AUTOSAR XML (schema 4-2-2)
package /ComponentTypes
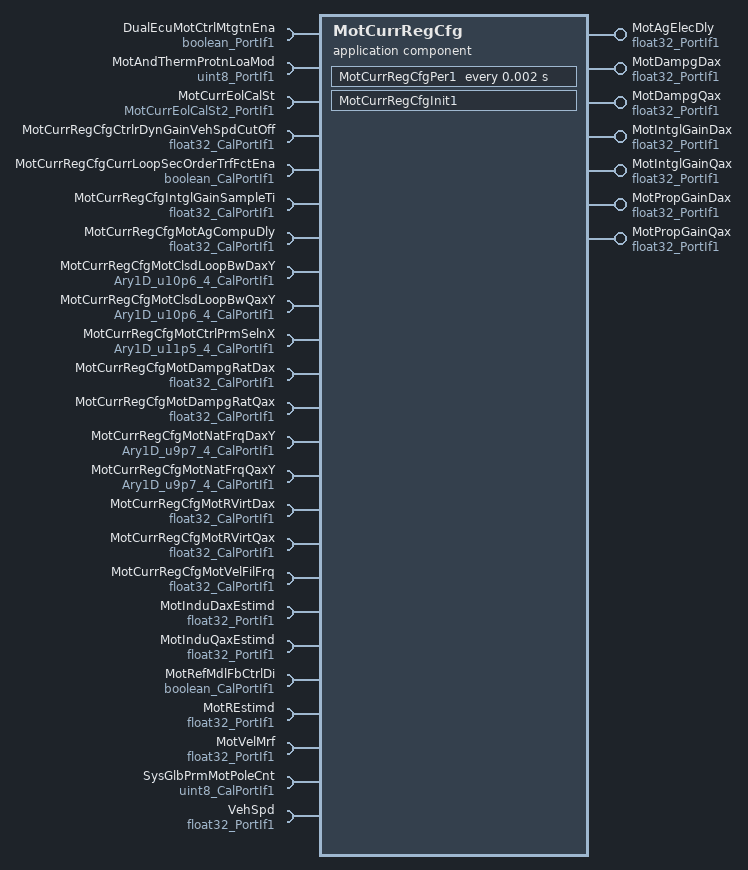
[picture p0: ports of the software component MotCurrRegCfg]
  application sw component type MotCurrRegCfg
    7 x provide port, all with nonqueued-sender-com-spec{data-element=Val, init-value=0}, provided-interface=float32_PortIf1:
      MotAgElecDly
      MotDampgDax
      MotDampgQax
      MotIntglGainDax
      MotIntglGainQax
      MotPropGainDax
      MotPropGainQax
    24 x require port:
      DualEcuMotCtrlMtgtnEna: nonqueued-receiver-com-spec{data-element=Logl, filter=data-filter-type=ALWAYS, init-value=0}, required-interface=boolean_PortIf1
      MotAndThermProtnLoaMod: nonqueued-receiver-com-spec{data-element=Val, filter=data-filter-type=ALWAYS, init-value=0}, required-interface=uint8_PortIf1
      MotCurrEolCalSt: nonqueued-receiver-com-spec{data-element=Val, filter=data-filter-type=ALWAYS, init-value=0}, required-interface=MotCurrEolCalSt2_PortIf1
      MotCurrRegCfgCtrlrDynGainVehSpdCutOff: parameter-require-com-spec{init-value=255, parameter=Val}, required-interface=float32_CalPortIf1
      MotCurrRegCfgCurrLoopSecOrderTrfFctEna: parameter-require-com-spec{init-value=1, parameter=Logl}, required-interface=boolean_CalPortIf1
      MotCurrRegCfgIntglGainSampleTi: parameter-require-com-spec{init-value=0.000125, parameter=Val}, required-interface=float32_CalPortIf1
      MotCurrRegCfgMotAgCompuDly: parameter-require-com-spec{init-value=9.375e-05, parameter=Val}, required-interface=float32_CalPortIf1
      MotCurrRegCfgMotClsdLoopBwDaxY: parameter-require-com-spec{init-value=[12800, 19200, 19200, 19200], parameter=Ary1D}, required-interface=Ary1D_u10p6_4_CalPortIf1
      MotCurrRegCfgMotClsdLoopBwQaxY: parameter-require-com-spec{init-value=[12800, 19200, 19200, 19200], parameter=Ary1D}, required-interface=Ary1D_u10p6_4_CalPortIf1
      MotCurrRegCfgMotCtrlPrmSelnX: parameter-require-com-spec{init-value=[0, 32, 160, 320], parameter=Ary1D}, required-interface=Ary1D_u11p5_4_CalPortIf1
      MotCurrRegCfgMotDampgRatDax: parameter-require-com-spec{init-value=1, parameter=Val}, required-interface=float32_CalPortIf1
      MotCurrRegCfgMotDampgRatQax: parameter-require-com-spec{init-value=1, parameter=Val}, required-interface=float32_CalPortIf1
      MotCurrRegCfgMotNatFrqDaxY: parameter-require-com-spec{init-value=[38400, 38400, 38400, 38400], parameter=Ary1D}, required-interface=Ary1D_u9p7_4_CalPortIf1
      MotCurrRegCfgMotNatFrqQaxY: parameter-require-com-spec{init-value=[38400, 38400, 38400, 38400], parameter=Ary1D}, required-interface=Ary1D_u9p7_4_CalPortIf1
      MotCurrRegCfgMotRVirtDax: parameter-require-com-spec{init-value=0, parameter=Val}, required-interface=float32_CalPortIf1
      MotCurrRegCfgMotRVirtQax: parameter-require-com-spec{init-value=0, parameter=Val}, required-interface=float32_CalPortIf1
      MotCurrRegCfgMotVelFilFrq: parameter-require-com-spec{init-value=10, parameter=Val}, required-interface=float32_CalPortIf1
      MotInduDaxEstimd: nonqueued-receiver-com-spec{data-element=Val, filter=data-filter-type=ALWAYS, init-value=0.00011889}, required-interface=float32_PortIf1
      MotInduQaxEstimd: nonqueued-receiver-com-spec{data-element=Val, filter=data-filter-type=ALWAYS, init-value=0.00011889}, required-interface=float32_PortIf1
      MotRefMdlFbCtrlDi: parameter-require-com-spec{init-value=0, parameter=Logl}, required-interface=boolean_CalPortIf1
      MotREstimd: nonqueued-receiver-com-spec{data-element=Val, filter=data-filter-type=ALWAYS, init-value=0.0139083}, required-interface=float32_PortIf1
      MotVelMrf: nonqueued-receiver-com-spec{data-element=Val, filter=data-filter-type=ALWAYS, init-value=0}, required-interface=float32_PortIf1
      SysGlbPrmMotPoleCnt: parameter-require-com-spec{init-value=8, parameter=Val}, required-interface=uint8_CalPortIf1
      VehSpd: nonqueued-receiver-com-spec{data-element=Val, filter=data-filter-type=ALWAYS, init-value=0}, required-interface=float32_PortIf1
    behavior MotCurrRegCfg_InternalBehavior
      ar-typed-per-instance-memorys:
        data dMotCurrRegCfgMotVelMrfFild: sw-calibration-access=READ-ONLY, type=float32
        data MotVelMrfFild: sw-calibration-access=READ-ONLY, type=FilLpRec1
      init event MotCurrRegCfg_InitEvent: start-on-event=MotCurrRegCfgInit1
      timing event TMT_MotCurrRegCfgPer1: start-on-event=MotCurrRegCfgPer1, period=0.002
      port-api-options:
        enable-take-address=false, error-handling=NO-TRANSFORMER-ERROR-HANDLING, indirect-api=false, port=DualEcuMotCtrlMtgtnEna
        enable-take-address=false, error-handling=NO-TRANSFORMER-ERROR-HANDLING, indirect-api=false, port=MotAgElecDly
        enable-take-address=false, error-handling=NO-TRANSFORMER-ERROR-HANDLING, indirect-api=false, port=MotAndThermProtnLoaMod
        enable-take-address=false, error-handling=NO-TRANSFORMER-ERROR-HANDLING, indirect-api=false, port=MotCurrEolCalSt
        enable-take-address=false, error-handling=NO-TRANSFORMER-ERROR-HANDLING, indirect-api=false, port=MotCurrRegCfgCtrlrDynGainVehSpdCutOff
        enable-take-address=false, error-handling=NO-TRANSFORMER-ERROR-HANDLING, indirect-api=false, port=MotCurrRegCfgCurrLoopSecOrderTrfFctEna
        enable-take-address=false, error-handling=NO-TRANSFORMER-ERROR-HANDLING, indirect-api=false, port=MotCurrRegCfgIntglGainSampleTi
        enable-take-address=false, error-handling=NO-TRANSFORMER-ERROR-HANDLING, indirect-api=false, port=MotCurrRegCfgMotAgCompuDly
        enable-take-address=false, error-handling=NO-TRANSFORMER-ERROR-HANDLING, indirect-api=false, port=MotCurrRegCfgMotClsdLoopBwDaxY
        enable-take-address=false, error-handling=NO-TRANSFORMER-ERROR-HANDLING, indirect-api=false, port=MotCurrRegCfgMotClsdLoopBwQaxY
        enable-take-address=false, error-handling=NO-TRANSFORMER-ERROR-HANDLING, indirect-api=false, port=MotCurrRegCfgMotCtrlPrmSelnX
        enable-take-address=false, error-handling=NO-TRANSFORMER-ERROR-HANDLING, indirect-api=false, port=MotCurrRegCfgMotDampgRatDax
        enable-take-address=false, error-handling=NO-TRANSFORMER-ERROR-HANDLING, indirect-api=false, port=MotCurrRegCfgMotDampgRatQax
        enable-take-address=false, error-handling=NO-TRANSFORMER-ERROR-HANDLING, indirect-api=false, port=MotCurrRegCfgMotNatFrqDaxY
        enable-take-address=false, error-handling=NO-TRANSFORMER-ERROR-HANDLING, indirect-api=false, port=MotCurrRegCfgMotNatFrqQaxY
        enable-take-address=false, error-handling=NO-TRANSFORMER-ERROR-HANDLING, indirect-api=false, port=MotCurrRegCfgMotRVirtDax
        enable-take-address=false, error-handling=NO-TRANSFORMER-ERROR-HANDLING, indirect-api=false, port=MotCurrRegCfgMotRVirtQax
        enable-take-address=false, error-handling=NO-TRANSFORMER-ERROR-HANDLING, indirect-api=false, port=MotCurrRegCfgMotVelFilFrq
        enable-take-address=false, error-handling=NO-TRANSFORMER-ERROR-HANDLING, indirect-api=false, port=MotDampgDax
        enable-take-address=false, error-handling=NO-TRANSFORMER-ERROR-HANDLING, indirect-api=false, port=MotDampgQax
        enable-take-address=false, error-handling=NO-TRANSFORMER-ERROR-HANDLING, indirect-api=false, port=MotInduDaxEstimd
        enable-take-address=false, error-handling=NO-TRANSFORMER-ERROR-HANDLING, indirect-api=false, port=MotInduQaxEstimd
        enable-take-address=false, error-handling=NO-TRANSFORMER-ERROR-HANDLING, indirect-api=false, port=MotIntglGainDax
        enable-take-address=false, error-handling=NO-TRANSFORMER-ERROR-HANDLING, indirect-api=false, port=MotIntglGainQax
        enable-take-address=false, error-handling=NO-TRANSFORMER-ERROR-HANDLING, indirect-api=false, port=MotPropGainDax
        enable-take-address=false, error-handling=NO-TRANSFORMER-ERROR-HANDLING, indirect-api=false, port=MotPropGainQax
        enable-take-address=false, error-handling=NO-TRANSFORMER-ERROR-HANDLING, indirect-api=false, port=MotRefMdlFbCtrlDi
        enable-take-address=false, error-handling=NO-TRANSFORMER-ERROR-HANDLING, indirect-api=false, port=MotREstimd
        enable-take-address=false, error-handling=NO-TRANSFORMER-ERROR-HANDLING, indirect-api=false, port=SysGlbPrmMotPoleCnt
        enable-take-address=false, error-handling=NO-TRANSFORMER-ERROR-HANDLING, indirect-api=false, port=VehSpd
      runnable MotCurrRegCfgInit1
      runnable MotCurrRegCfgPer1
        data-receive-point-by-arguments:
          8 x access:
            REC_DualEcuMotCtrlMtgtnEna_Logl: accessed-variable=DualEcuMotCtrlMtgtnEna.Logl
            REC_MotAndThermProtnLoaMod_Val: accessed-variable=MotAndThermProtnLoaMod.Val
            REC_MotCurrEolCalSt_Val: accessed-variable=MotCurrEolCalSt.Val
            REC_MotInduDaxEstimd_Val: accessed-variable=MotInduDaxEstimd.Val
            REC_MotInduQaxEstimd_Val: accessed-variable=MotInduQaxEstimd.Val
            REC_MotREstimd_Val: accessed-variable=MotREstimd.Val
            REC_MotVelMrf_Val: accessed-variable=MotVelMrf.Val
            REC_VehSpd_Val: accessed-variable=VehSpd.Val
        data-send-points:
          7 x access:
            SEND_MotAgElecDly_Val: accessed-variable=MotAgElecDly.Val
            SEND_MotDampgDax_Val: accessed-variable=MotDampgDax.Val
            SEND_MotDampgQax_Val: accessed-variable=MotDampgQax.Val
            SEND_MotIntglGainDax_Val: accessed-variable=MotIntglGainDax.Val
            SEND_MotIntglGainQax_Val: accessed-variable=MotIntglGainQax.Val
            SEND_MotPropGainDax_Val: accessed-variable=MotPropGainDax.Val
            SEND_MotPropGainQax_Val: accessed-variable=MotPropGainQax.Val
  swc implementation MotCurrRegCfg_Implementation: behavior=MotCurrRegCfg_InternalBehavior
    code-descriptors:
      code Default: artifact-descriptors=autosar-engineering-object={short-label=Default, category=SWSRC}
